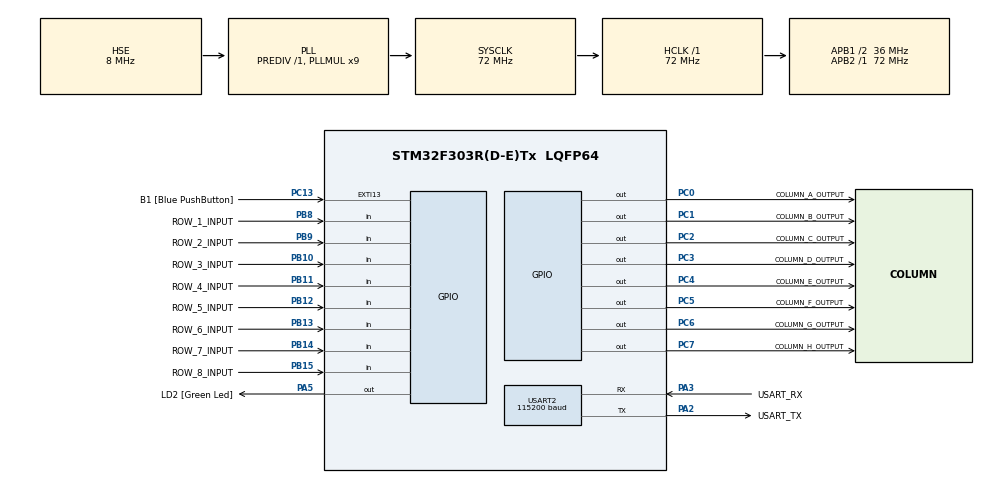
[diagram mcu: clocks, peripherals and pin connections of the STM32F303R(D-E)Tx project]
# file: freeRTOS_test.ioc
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FREERTOS.Queues01=mplexQueue,16,uint8_t,0,Dynamic,NULL,NULL
FREERTOS.Tasks01=defaultTask,-3,128,StartDefaultTask,Default,NULL,Dynamic,NULL,NULL;multiplexerTask,0,128,StartMultiplexerTask,As weak,NULL,Dynamic,NULL,NULL;ledTask,-2,128,StartLedTask,As weak,NULL,Dynamic,NULL,NULL;comTask,0,128,StartComTask,As weak,NULL,Dynamic,NULL,NULL;chessboardTask,-3,128,StartChessboardTask,As weak,NULL,Dynamic,NULL,NULL
FREERTOS.configTOTAL_HEAP_SIZE=6144
Mcu.Family=STM32F3
Mcu.Name=STM32F303R(D-E)Tx
Mcu.Package=LQFP64
NVIC.PriorityGroup=NVIC_PRIORITYGROUP_4
NVIC.USART2_IRQn=true\:5\:0\:false\:true\:true\:1\:true\:true
PA13.GPIO_Label=TMS
PA13.Mode=Serial_Wire
PA13.Signal=SYS_JTMS-SWDIO
PA14.GPIO_Label=TCK
PA14.Mode=Serial_Wire
PA14.Signal=SYS_JTCK-SWCLK
PA2.GPIO_Label=USART_TX
PA2.GPIO_Mode=GPIO_MODE_AF_PP
PA2.GPIO_PuPd=GPIO_NOPULL
PA2.GPIO_Speed=GPIO_SPEED_FREQ_LOW
PA2.Mode=Asynchronous
PA2.Signal=USART2_TX
PA3.GPIO_Label=USART_RX
PA3.GPIO_Mode=GPIO_MODE_AF_PP
PA3.GPIO_PuPd=GPIO_NOPULL
PA3.GPIO_Speed=GPIO_SPEED_FREQ_LOW
PA3.Mode=Asynchronous
PA3.Signal=USART2_RX
PA5.GPIO_Label=LD2 [Green Led]
PA5.GPIO_Mode=GPIO_MODE_OUTPUT_PP
PA5.GPIO_PuPd=GPIO_NOPULL
PA5.GPIO_Speed=GPIO_SPEED_FREQ_LOW
PA5.Signal=GPIO_Output
PB10.GPIO_Label=ROW_3_INPUT
PB10.GPIO_PuPd=GPIO_PULLDOWN
PB10.Signal=GPIO_Input
PB11.GPIO_Label=ROW_4_INPUT
PB11.GPIO_PuPd=GPIO_PULLDOWN
PB11.Signal=GPIO_Input
PB12.GPIO_Label=ROW_5_INPUT
PB12.GPIO_PuPd=GPIO_PULLDOWN
PB12.Signal=GPIO_Input
PB13.GPIO_Label=ROW_6_INPUT
PB13.GPIO_PuPd=GPIO_PULLDOWN
PB13.Signal=GPIO_Input
PB14.GPIO_Label=ROW_7_INPUT
PB14.GPIO_PuPd=GPIO_PULLDOWN
PB14.Signal=GPIO_Input
PB15.GPIO_Label=ROW_8_INPUT
PB15.GPIO_PuPd=GPIO_PULLDOWN
PB15.Signal=GPIO_Input
PB3.GPIO_Label=SWO
PB3.Signal=SYS_JTDO-TRACESWO
PB8.GPIO_Label=ROW_1_INPUT
PB8.GPIO_PuPd=GPIO_PULLDOWN
PB8.Signal=GPIO_Input
PB9.GPIO_Label=ROW_2_INPUT
PB9.GPIO_PuPd=GPIO_PULLDOWN
PB9.Signal=GPIO_Input
PC0.GPIO_Label=COLUMN_A_OUTPUT
PC0.Signal=GPIO_Output
PC1.GPIO_Label=COLUMN_B_OUTPUT
PC1.Signal=GPIO_Output
PC13.GPIO_Label=B1 [Blue PushButton]
PC13.GPIO_ModeDefaultEXTI=GPIO_MODE_IT_FALLING
PC13.Signal=GPXTI13
PC14-OSC32_IN.Mode=LSE-External-Oscillator
PC14-OSC32_IN.Signal=RCC_OSC32_IN
PC15-OSC32_OUT.Mode=LSE-External-Oscillator
PC15-OSC32_OUT.Signal=RCC_OSC32_OUT
PC2.GPIO_Label=COLUMN_C_OUTPUT
PC2.Signal=GPIO_Output
PC3.GPIO_Label=COLUMN_D_OUTPUT
PC3.Signal=GPIO_Output
PC4.GPIO_Label=COLUMN_E_OUTPUT
PC4.Signal=GPIO_Output
PC5.GPIO_Label=COLUMN_F_OUTPUT
PC5.Signal=GPIO_Output
PC6.GPIO_Label=COLUMN_G_OUTPUT
PC6.Signal=GPIO_Output
PC7.GPIO_Label=COLUMN_H_OUTPUT
PC7.Signal=GPIO_Output
PF0-OSC_IN.Mode=HSE-External-Clock-Source
PF0-OSC_IN.Signal=RCC_OSC_IN
PF1-OSC_OUT.Signal=RCC_OSC_OUT
ProjectManager.HeapSize=0x200
ProjectManager.StackSize=0x400
ProjectManager.TargetToolchain=TrueSTUDIO
RCC.AHBFreq_Value=72000000
RCC.APB1CLKDivider=RCC_HCLK_DIV2
RCC.APB1Freq_Value=36000000
RCC.APB1TimFreq_Value=72000000
RCC.APB2Freq_Value=72000000
RCC.APB2TimFreq_Value=72000000
RCC.CortexFreq_Value=72000000
RCC.HCLKFreq_Value=72000000
RCC.HSE_VALUE=8000000
RCC.HSI_VALUE=8000000
RCC.PLLM=8
RCC.PLLMUL=RCC_PLL_MUL9
RCC.PLLN=336
RCC.PLLP=RCC_PLLP_DIV4
RCC.PLLQ=7
RCC.PLLSourceVirtual=RCC_PLLSOURCE_HSE
RCC.PRESCALERUSB=RCC_USBCLKSOURCE_PLL_DIV1_5
RCC.RCC_PLLsource_Clock_Source_FROM_HSE=RCC_HSE_PREDIV_DIV2
RCC.SYSCLKFreq_VALUE=72000000
RCC.SYSCLKSourceVirtual=RCC_SYSCLKSOURCE_PLLCLK
RCC.USBFreq_Value=48000000
USART2.BaudRate=115200
USART2.VirtualMode-Asynchronous=VM_ASYNC
VP_FREERTOS_VS_ENABLE.Mode=Enabled
board=NUCLEO-F303RE

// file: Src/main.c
/* USER CODE BEGIN Header */
/**
  ******************************************************************************
  * @file           : main.c
  * @brief          : Main program body
  ******************************************************************************
  * This notice applies to any and all portions of this file
  * that are not between comment pairs USER CODE BEGIN and
  * USER CODE END. Other portions of this file, whether
  * inserted by the user or by software development tools
  * are owned by their respective copyright owners.
  *
  * Copyright (c) 2019 STMicroelectronics International N.V.
  * All rights reserved.
  *
  * Redistribution and use in source and binary forms, with or without
  * modification, are permitted, provided that the following conditions are met:
  *
  * 1. Redistribution of source code must retain the above copyright notice,
  *    this list of conditions and the following disclaimer.
  * 2. Redistributions in binary form must reproduce the above copyright notice,
  *    this list of conditions and the following disclaimer in the documentation
  *    and/or other materials provided with the distribution.
  * 3. Neither the name of STMicroelectronics nor the names of other
  *    contributors to this software may be used to endorse or promote products
  *    derived from this software without specific written permission.
  * 4. This software, including modifications and/or derivative works of this
  *    software, must execute solely and exclusively on microcontroller or
  *    microprocessor devices manufactured by or for STMicroelectronics.
  * 5. Redistribution and use of this software other than as permitted under
  *    this license is void and will automatically terminate your rights under
  *    this license.
  *
  * THIS SOFTWARE IS PROVIDED BY STMICROELECTRONICS AND CONTRIBUTORS "AS IS"
  * AND ANY EXPRESS, IMPLIED OR STATUTORY WARRANTIES, INCLUDING, BUT NOT
  * LIMITED TO, THE IMPLIED WARRANTIES OF MERCHANTABILITY, FITNESS FOR A
  * PARTICULAR PURPOSE AND NON-INFRINGEMENT OF THIRD PARTY INTELLECTUAL PROPERTY
  * RIGHTS ARE DISCLAIMED TO THE FULLEST EXTENT PERMITTED BY LAW. IN NO EVENT
  * SHALL STMICROELECTRONICS OR CONTRIBUTORS BE LIABLE FOR ANY DIRECT, INDIRECT,
  * INCIDENTAL, SPECIAL, EXEMPLARY, OR CONSEQUENTIAL DAMAGES (INCLUDING, BUT NOT
  * LIMITED TO, PROCUREMENT OF SUBSTITUTE GOODS OR SERVICES; LOSS OF USE, DATA,
  * OR PROFITS; OR BUSINESS INTERRUPTION) HOWEVER CAUSED AND ON ANY THEORY OF
  * LIABILITY, WHETHER IN CONTRACT, STRICT LIABILITY, OR TORT (INCLUDING
  * NEGLIGENCE OR OTHERWISE) ARISING IN ANY WAY OUT OF THE USE OF THIS SOFTWARE,
  * EVEN IF ADVISED OF THE POSSIBILITY OF SUCH DAMAGE.
  *
  ******************************************************************************
  */
/* USER CODE END Header */

#include "main.h"
#include "cmsis_os.h"
#include "usart.h"
#include "gpio.h"

/* USER CODE BEGIN Includes */
#include "multiplexer.h"
/* USER CODE END Includes */

/* USER CODE BEGIN PV */
//Multiplexer mplex;
/* USER CODE END PV */

void SystemClock_Config(void);
void MX_FREERTOS_Init(void);
static void MX_NVIC_Init(void);

int main(void)
{

  /* MCU Configuration--------------------------------------------------------*/

  /* Reset of all peripherals, Initializes the Flash interface and the Systick. */
  HAL_Init();

  /* Configure the system clock */
  SystemClock_Config();

  /* Initialize all configured peripherals */
  MX_GPIO_Init();
  MX_USART2_UART_Init();

  /* Initialize interrupts */
  MX_NVIC_Init();

  /* Call init function for freertos objects (in freertos.c) */
  MX_FREERTOS_Init();

  /* Start scheduler */
  osKernelStart();

  /* We should never get here as control is now taken by the scheduler */

  /* Infinite loop */
  /* USER CODE BEGIN WHILE */
//	Multiplexer mplex;
//	init(&mplex);
  while (1)
  {
//	  HAL_Delay(50);
    /* USER CODE END WHILE */

    /* USER CODE BEGIN 3 */
//	  scan(&mplex);
  }
  /* USER CODE END 3 */
}

void SystemClock_Config(void)
{
  RCC_OscInitTypeDef RCC_OscInitStruct = {0};
  RCC_ClkInitTypeDef RCC_ClkInitStruct = {0};
  RCC_PeriphCLKInitTypeDef PeriphClkInit = {0};

  /**Initializes the CPU, AHB and APB busses clocks
  */
  RCC_OscInitStruct.OscillatorType = RCC_OSCILLATORTYPE_HSE;
  RCC_OscInitStruct.HSEState = RCC_HSE_BYPASS;
  RCC_OscInitStruct.HSIState = RCC_HSI_ON;
  RCC_OscInitStruct.PLL.PLLState = RCC_PLL_ON;
  RCC_OscInitStruct.PLL.PLLSource = RCC_PLLSOURCE_HSE;
  RCC_OscInitStruct.PLL.PLLMUL = RCC_PLL_MUL9;
  RCC_OscInitStruct.PLL.PREDIV = RCC_PREDIV_DIV1;
  if (HAL_RCC_OscConfig(&RCC_OscInitStruct) != HAL_OK)
  {
    Error_Handler();
  }
  /**Initializes the CPU, AHB and APB busses clocks
  */
  RCC_ClkInitStruct.ClockType = RCC_CLOCKTYPE_HCLK|RCC_CLOCKTYPE_SYSCLK
                              |RCC_CLOCKTYPE_PCLK1|RCC_CLOCKTYPE_PCLK2;
  RCC_ClkInitStruct.SYSCLKSource = RCC_SYSCLKSOURCE_PLLCLK;
  RCC_ClkInitStruct.AHBCLKDivider = RCC_SYSCLK_DIV1;
  RCC_ClkInitStruct.APB1CLKDivider = RCC_HCLK_DIV2;
  RCC_ClkInitStruct.APB2CLKDivider = RCC_HCLK_DIV1;

  if (HAL_RCC_ClockConfig(&RCC_ClkInitStruct, FLASH_LATENCY_2) != HAL_OK)
  {
    Error_Handler();
  }
  PeriphClkInit.PeriphClockSelection = RCC_PERIPHCLK_USART2;
  PeriphClkInit.Usart2ClockSelection = RCC_USART2CLKSOURCE_PCLK1;
  if (HAL_RCCEx_PeriphCLKConfig(&PeriphClkInit) != HAL_OK)
  {
    Error_Handler();
  }
}

/**
  * @brief NVIC Configuration.
  * @retval None
  */
static void MX_NVIC_Init(void)
{
  /* USART2_IRQn interrupt configuration */
  HAL_NVIC_SetPriority(USART2_IRQn, 5, 0);
  HAL_NVIC_EnableIRQ(USART2_IRQn);
}

void Error_Handler(void)
{
}

/************************ (C) COPYRIGHT STMicroelectronics *****END OF FILE****/

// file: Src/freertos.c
/* USER CODE BEGIN Header */
/**
  ******************************************************************************
  * File Name          : freertos.c
  * Description        : Code for freertos applications
  ******************************************************************************
  * This notice applies to any and all portions of this file
  * that are not between comment pairs USER CODE BEGIN and
  * USER CODE END. Other portions of this file, whether
  * inserted by the user or by software development tools
  * are owned by their respective copyright owners.
  *
  * Copyright (c) 2019 STMicroelectronics International N.V.
  * All rights reserved.
  *
  * Redistribution and use in source and binary forms, with or without
  * modification, are permitted, provided that the following conditions are met:
  *
  * 1. Redistribution of source code must retain the above copyright notice,
  *    this list of conditions and the following disclaimer.
  * 2. Redistributions in binary form must reproduce the above copyright notice,
  *    this list of conditions and the following disclaimer in the documentation
  *    and/or other materials provided with the distribution.
  * 3. Neither the name of STMicroelectronics nor the names of other
  *    contributors to this software may be used to endorse or promote products
  *    derived from this software without specific written permission.
  * 4. This software, including modifications and/or derivative works of this
  *    software, must execute solely and exclusively on microcontroller or
  *    microprocessor devices manufactured by or for STMicroelectronics.
  * 5. Redistribution and use of this software other than as permitted under
  *    this license is void and will automatically terminate your rights under
  *    this license.
  *
  * THIS SOFTWARE IS PROVIDED BY STMICROELECTRONICS AND CONTRIBUTORS "AS IS"
  * AND ANY EXPRESS, IMPLIED OR STATUTORY WARRANTIES, INCLUDING, BUT NOT
  * LIMITED TO, THE IMPLIED WARRANTIES OF MERCHANTABILITY, FITNESS FOR A
  * PARTICULAR PURPOSE AND NON-INFRINGEMENT OF THIRD PARTY INTELLECTUAL PROPERTY
  * RIGHTS ARE DISCLAIMED TO THE FULLEST EXTENT PERMITTED BY LAW. IN NO EVENT
  * SHALL STMICROELECTRONICS OR CONTRIBUTORS BE LIABLE FOR ANY DIRECT, INDIRECT,
  * INCIDENTAL, SPECIAL, EXEMPLARY, OR CONSEQUENTIAL DAMAGES (INCLUDING, BUT NOT
  * LIMITED TO, PROCUREMENT OF SUBSTITUTE GOODS OR SERVICES; LOSS OF USE, DATA,
  * OR PROFITS; OR BUSINESS INTERRUPTION) HOWEVER CAUSED AND ON ANY THEORY OF
  * LIABILITY, WHETHER IN CONTRACT, STRICT LIABILITY, OR TORT (INCLUDING
  * NEGLIGENCE OR OTHERWISE) ARISING IN ANY WAY OUT OF THE USE OF THIS SOFTWARE,
  * EVEN IF ADVISED OF THE POSSIBILITY OF SUCH DAMAGE.
  *
  ******************************************************************************
  */
/* USER CODE END Header */

#include "FreeRTOS.h"
#include "task.h"
#include "main.h"
#include "cmsis_os.h"

osThreadId defaultTaskHandle;
osThreadId multiplexerTaskHandle;
osThreadId ledTaskHandle;
osThreadId comTaskHandle;
osThreadId chessboardTaskHandle;
osMessageQId mplexQueueHandle;

void StartDefaultTask(void const * argument);
void StartMultiplexerTask(void const * argument);
void StartLedTask(void const * argument);
void StartComTask(void const * argument);
void StartChessboardTask(void const * argument);

void MX_FREERTOS_Init(void); /* (MISRA C 2004 rule 8.1) */

void MX_FREERTOS_Init(void) {

  /* Create the thread(s) */
  /* definition and creation of defaultTask */
  osThreadDef(defaultTask, StartDefaultTask, osPriorityIdle, 0, 128);
  defaultTaskHandle = osThreadCreate(osThread(defaultTask), NULL);

  /* definition and creation of multiplexerTask */
  osThreadDef(multiplexerTask, StartMultiplexerTask, osPriorityNormal, 0, 128);
  multiplexerTaskHandle = osThreadCreate(osThread(multiplexerTask), NULL);

  /* definition and creation of ledTask */
  osThreadDef(ledTask, StartLedTask, osPriorityLow, 0, 128);
  ledTaskHandle = osThreadCreate(osThread(ledTask), NULL);

  /* definition and creation of comTask */
  osThreadDef(comTask, StartComTask, osPriorityNormal, 0, 128);
  comTaskHandle = osThreadCreate(osThread(comTask), NULL);

  /* definition and creation of chessboardTask */
  osThreadDef(chessboardTask, StartChessboardTask, osPriorityIdle, 0, 128);
  chessboardTaskHandle = osThreadCreate(osThread(chessboardTask), NULL);

  /* Create the queue(s) */
  /* definition and creation of mplexQueue */
  osMessageQDef(mplexQueue, 16, uint8_t);
  mplexQueueHandle = osMessageCreate(osMessageQ(mplexQueue), NULL);

}

void StartDefaultTask(void const * argument)
{

  for(;;)
  {
    osDelay(1);
  }
}

__weak void StartMultiplexerTask(void const * argument)
{
  for(;;)
  {
    osDelay(1);
  }
}

__weak void StartLedTask(void const * argument)
{
  for(;;)
  {
    osDelay(1);
  }
}

__weak void StartComTask(void const * argument)
{
  for(;;)
  {
    osDelay(1);
  }
}

__weak void StartChessboardTask(void const * argument)
{
  for(;;)
  {
    osDelay(1);
  }
}

/************************ (C) COPYRIGHT STMicroelectronics *****END OF FILE****/
